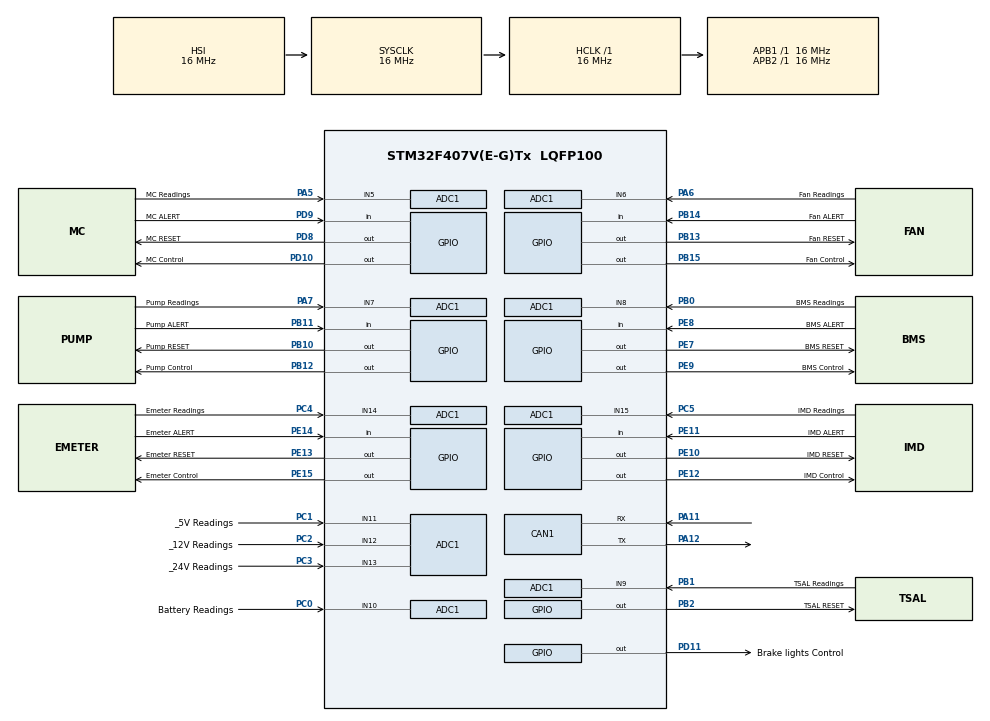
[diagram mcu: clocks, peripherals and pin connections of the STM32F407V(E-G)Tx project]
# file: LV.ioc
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ADC1.Channel-0\#ChannelRegularConversion=ADC_CHANNEL_10
ADC1.NbrOfConversionFlag=1
ADC1.Rank-0\#ChannelRegularConversion=1
ADC1.SamplingTime-0\#ChannelRegularConversion=ADC_SAMPLETIME_3CYCLES
ADC1.master=1
CAN1.CalculateTimeBit=3000
CAN1.CalculateTimeQuantum=1000.0
Mcu.Family=STM32F4
Mcu.Name=STM32F407V(E-G)Tx
Mcu.Package=LQFP100
NVIC.PriorityGroup=NVIC_PRIORITYGROUP_4
PA11.Mode=Master
PA11.Signal=CAN1_RX
PA12.Mode=Master
PA12.Signal=CAN1_TX
PA13.Mode=Serial_Wire
PA13.Signal=SYS_JTMS-SWDIO
PA14.Mode=Serial_Wire
PA14.Signal=SYS_JTCK-SWCLK
PA5.GPIO_Label=MC Readings
PA5.Signal=ADCx_IN5
PA6.GPIO_Label=Fan Readings
PA6.Signal=ADCx_IN6
PA7.GPIO_Label=Pump Readings
PA7.Signal=ADCx_IN7
PB0.GPIO_Label=BMS Readings
PB0.Signal=ADCx_IN8
PB1.GPIO_Label=TSAL Readings
PB1.Signal=ADCx_IN9
PB10.GPIO_Label=Pump RESET
PB10.Signal=GPIO_Output
PB11.GPIO_Label=Pump ALERT
PB11.Signal=GPIO_Input
PB12.GPIO_Label=Pump Control
PB12.Signal=GPIO_Output
PB13.GPIO_Label=Fan RESET
PB13.Signal=GPIO_Output
PB14.GPIO_Label=Fan ALERT
PB14.Signal=GPIO_Input
PB15.GPIO_Label=Fan Control
PB15.Signal=GPIO_Output
PB2.GPIO_Label=TSAL RESET
PB2.Signal=GPIO_Output
PC0.GPIO_Label=Battery Readings
PC0.Signal=ADCx_IN10
PC1.GPIO_Label=_5V Readings
PC1.Signal=ADCx_IN11
PC14-OSC32_IN.Signal=RCC_OSC32_IN
PC2.GPIO_Label=_12V Readings
PC2.Signal=ADCx_IN12
PC3.GPIO_Label=_24V Readings
PC3.Signal=ADCx_IN13
PC4.GPIO_Label=Emeter Readings
PC4.Signal=ADCx_IN14
PC5.GPIO_Label=IMD Readings
PC5.Signal=ADCx_IN15
PD10.GPIO_Label=MC Control
PD10.Signal=GPIO_Output
PD11.GPIO_Label=Brake lights Control
PD11.Signal=GPIO_Output
PD8.GPIO_Label=MC RESET
PD8.Signal=GPIO_Output
PD9.GPIO_Label=MC ALERT
PD9.Signal=GPIO_Input
PE10.GPIO_Label=IMD RESET
PE10.Signal=GPIO_Output
PE11.GPIO_Label=IMD ALERT
PE11.Signal=GPIO_Input
PE12.GPIO_Label=IMD Control
PE12.Signal=GPIO_Output
PE13.GPIO_Label=Emeter RESET
PE13.Signal=GPIO_Output
PE14.GPIO_Label=Emeter ALERT
PE14.Signal=GPIO_Input
PE15.GPIO_Label=Emeter Control
PE15.Signal=GPIO_Output
PE7.GPIO_Label=BMS RESET
PE7.Signal=GPIO_Output
PE8.GPIO_Label=BMS ALERT
PE8.Signal=GPIO_Input
PE9.GPIO_Label=BMS Control
PE9.Signal=GPIO_Output
PH0-OSC_IN.Signal=RCC_OSC_IN
ProjectManager.HeapSize=0x200
ProjectManager.StackSize=0x400
ProjectManager.TargetToolchain=TrueSTUDIO
RCC.AHBFreq_Value=16000000
RCC.APB1Freq_Value=16000000
RCC.APB2Freq_Value=16000000
RCC.CortexFreq_Value=16000000
RCC.HSE_VALUE=25000000
RCC.HSI_VALUE=16000000
RCC.LSE_VALUE=32768
RCC.SYSCLKFreq_VALUE=16000000
RCC.VCOOutputFreq_Value=192000000
SH.ADCx_IN10.0=ADC1_IN10,IN10
SH.ADCx_IN11.0=ADC1_IN11,IN11
SH.ADCx_IN12.0=ADC1_IN12,IN12
SH.ADCx_IN13.0=ADC1_IN13,IN13
SH.ADCx_IN14.0=ADC1_IN14,IN14
SH.ADCx_IN15.0=ADC1_IN15,IN15
SH.ADCx_IN5.0=ADC1_IN5,IN5
SH.ADCx_IN6.0=ADC1_IN6,IN6
SH.ADCx_IN7.0=ADC1_IN7,IN7
SH.ADCx_IN8.0=ADC1_IN8,IN8
SH.ADCx_IN9.0=ADC1_IN9,IN9
board=LV

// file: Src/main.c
/**
  ******************************************************************************
  * File Name          : main.c
  * Description        : Main program body
  ******************************************************************************
  *
  * COPYRIGHT(c) 2016 STMicroelectronics
  *
  * Redistribution and use in source and binary forms, with or without modification,
  * are permitted provided that the following conditions are met:
  *   1. Redistributions of source code must retain the above copyright notice,
  *      this list of conditions and the following disclaimer.
  *   2. Redistributions in binary form must reproduce the above copyright notice,
  *      this list of conditions and the following disclaimer in the documentation
  *      and/or other materials provided with the distribution.
  *   3. Neither the name of STMicroelectronics nor the names of its contributors
  *      may be used to endorse or promote products derived from this software
  *      without specific prior written permission.
  *
  * THIS SOFTWARE IS PROVIDED BY THE COPYRIGHT HOLDERS AND CONTRIBUTORS "AS IS"
  * AND ANY EXPRESS OR IMPLIED WARRANTIES, INCLUDING, BUT NOT LIMITED TO, THE
  * IMPLIED WARRANTIES OF MERCHANTABILITY AND FITNESS FOR A PARTICULAR PURPOSE ARE
  * DISCLAIMED. IN NO EVENT SHALL THE COPYRIGHT HOLDER OR CONTRIBUTORS BE LIABLE
  * FOR ANY DIRECT, INDIRECT, INCIDENTAL, SPECIAL, EXEMPLARY, OR CONSEQUENTIAL
  * DAMAGES (INCLUDING, BUT NOT LIMITED TO, PROCUREMENT OF SUBSTITUTE GOODS OR
  * SERVICES; LOSS OF USE, DATA, OR PROFITS; OR BUSINESS INTERRUPTION) HOWEVER
  * CAUSED AND ON ANY THEORY OF LIABILITY, WHETHER IN CONTRACT, STRICT LIABILITY,
  * OR TORT (INCLUDING NEGLIGENCE OR OTHERWISE) ARISING IN ANY WAY OUT OF THE USE
  * OF THIS SOFTWARE, EVEN IF ADVISED OF THE POSSIBILITY OF SUCH DAMAGE.
  *
  ******************************************************************************
  */
#include "main.h"
#include "stm32f4xx_hal.h"
#include "adc.h"
#include "can.h"
#include "gpio.h"

/* USER CODE BEGIN PV */
/* Private variables ---------------------------------------------------------*/

/* USER CODE END PV */

void SystemClock_Config(void);
void Error_Handler(void);

/* USER CODE BEGIN PFP */
/* Private function prototypes -----------------------------------------------*/

/* USER CODE END PFP */

int main(void)
{

  /* USER CODE BEGIN 1 */
	uint32_t ADC_Values[11];
  /* USER CODE END 1 */

  /* MCU Configuration----------------------------------------------------------*/

  /* Reset of all peripherals, Initializes the Flash interface and the Systick. */
	HAL_Init();

  /* Configure the system clock */
	SystemClock_Config();

  /* Initialize all configured peripherals */
	MX_GPIO_Init();
	MX_ADC1_Init();
	MX_CAN1_Init();

  /* USER CODE BEGIN 2 */
	HAL_ADC_MspInit(&hadc1);
	HAL_ADC_Start(&hadc1);
  /* USER CODE END 2 */

  /* Infinite loop */
  while (1)
  {
  /* USER CODE BEGIN 3 */
	  HAL_ADC_PollForConversion(&hadc1, 1000) {
		  ADC_Values = HAL_ADC_GetValue(&hadc1);
	  }
  /* USER CODE END 3 */
  }
}
/** System Clock Configuration
*/
void SystemClock_Config(void)
{

  RCC_OscInitTypeDef RCC_OscInitStruct;
  RCC_ClkInitTypeDef RCC_ClkInitStruct;

    /**Configure the main internal regulator output voltage
    */
  __HAL_RCC_PWR_CLK_ENABLE();

  __HAL_PWR_VOLTAGESCALING_CONFIG(PWR_REGULATOR_VOLTAGE_SCALE1);

    /**Initializes the CPU, AHB and APB busses clocks
    */
  RCC_OscInitStruct.OscillatorType = RCC_OSCILLATORTYPE_HSI;
  RCC_OscInitStruct.HSIState = RCC_HSI_ON;
  RCC_OscInitStruct.HSICalibrationValue = 16;
  RCC_OscInitStruct.PLL.PLLState = RCC_PLL_NONE;
  if (HAL_RCC_OscConfig(&RCC_OscInitStruct) != HAL_OK)
  {
    Error_Handler();
  }

    /**Initializes the CPU, AHB and APB busses clocks
    */
  RCC_ClkInitStruct.ClockType = RCC_CLOCKTYPE_HCLK|RCC_CLOCKTYPE_SYSCLK
                              |RCC_CLOCKTYPE_PCLK1|RCC_CLOCKTYPE_PCLK2;
  RCC_ClkInitStruct.SYSCLKSource = RCC_SYSCLKSOURCE_HSI;
  RCC_ClkInitStruct.AHBCLKDivider = RCC_SYSCLK_DIV1;
  RCC_ClkInitStruct.APB1CLKDivider = RCC_HCLK_DIV1;
  RCC_ClkInitStruct.APB2CLKDivider = RCC_HCLK_DIV1;

  if (HAL_RCC_ClockConfig(&RCC_ClkInitStruct, FLASH_LATENCY_0) != HAL_OK)
  {
    Error_Handler();
  }

    /**Configure the Systick interrupt time
    */
  HAL_SYSTICK_Config(HAL_RCC_GetHCLKFreq()/1000);

    /**Configure the Systick
    */
  HAL_SYSTICK_CLKSourceConfig(SYSTICK_CLKSOURCE_HCLK);

  /* SysTick_IRQn interrupt configuration */
  HAL_NVIC_SetPriority(SysTick_IRQn, 0, 0);
}

/* USER CODE BEGIN 4 */
	HAL_ADC_Stop(ADC1);
	HAL_ADC_MspDeInit(ADC1);
/* USER CODE END 4 */

void Error_Handler(void)
{
  while(1)
  {
  }
}

/************************ (C) COPYRIGHT STMicroelectronics *****END OF FILE****/
